# EQEP_0 register map
Vendor: Texas Instruments
Peripheral module from a debugger description file (folder 66AK2G0x_66AK2G1x).
Registers are 16-bit, read-write, reset 0x0 unless marked. A register's access mark holds for its fields unless they carry their own. Offsets are as the file gives them; lines under a group give offsets from that group; [hi:lo] are bit positions; {n}, {i} and the like mark numbered series; 'fields as' and 'values as' point back to an identical list; <NAME> marks a mode.

## EQEP_0
0x00 EQEP_QPOSCNT 32-bit
  [31:0] QPOSCNT — This 32 bit position counter register counts up/down on every eQEP pulse based on direction input. This counter acts as a position integrator whose count value is proportional to position from a give reference point.
0x04 EQEP_QPOSINIT 32-bit
  [31:0] QPOSINIT — This register contains the position value that is used to initialize the position counter based on external strobe or index event. The position counter can be initialized through software.
0x08 EQEP_QPOSMAX 32-bit
  [31:0] QPOSMAX — This register contains the maximum position counter value.
0x0C EQEP_QPOSCMP 32-bit
  [31:0] QPOSCMP — The position-compare value in this register is compared with the position counter (
0x10 EQEP_QPOSILAT 32-bit ro
  [31:0] QPOSILAT — The position-counter value is latched into this register on an index event as defined by the
0x14 EQEP_QPOSSLAT 32-bit ro
  [31:0] QPOSSLAT — The position-counter value is latched into this register on strobe event as defined by the
0x18 EQEP_QPOSLAT 32-bit ro
  [31:0] QPOSLAT — The position-counter value is latched into this register on unit time out event.
0x1C EQEP_QUTMR 32-bit
  [31:0] QUTMR — This register acts as time base for unit time event generation. When this timer value matches with unit time period value, unit time event is generated.
0x20 EQEP_QUPRD 32-bit
  [31:0] QUPRD — This register contains the period count for unit timer to generate periodic unit time events to latch the eQEP position information at periodic interval and optionally to generate interrupt.
0x24 EQEP_QWDTMR
  [15:0] QWDTMR — This register acts as time base for watch dog to detect motor stalls. When this timer value matches with watch dog period value, watch dog timeout interrupt is generated. This register is reset upon edge transition in quadrature-clock indicating the motion.
0x26 EQEP_QWDPRD
  [15:0] QWDPRD — This register contains the time-out count for the eQEP peripheral watch dog timer. When the watchdog timer value matches the watchdog period value, a watchdog timeout interrupt is generated.
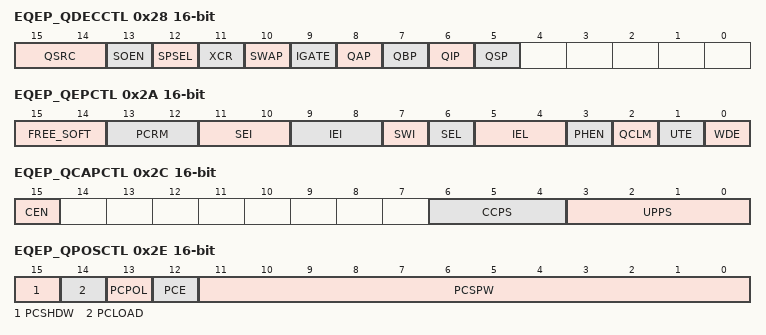
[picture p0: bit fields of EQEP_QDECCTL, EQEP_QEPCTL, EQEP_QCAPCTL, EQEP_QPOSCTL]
0x28 EQEP_QDECCTL access per field
  [15:14] QSRC rw — Position-counter source selection. 0h = Quadrature count mode (QCLK = iCLK, QDIR = iDIR) 1h = Direction-count mode (QCLK = xCLK, QDIR = xDIR) 2h = UP count mode for frequency measurement (QCLK = xCLK, QDIR = 1) 3h = DOWN count mode for frequency measurement (QCLK = xCLK, QDIR = 0)
  [13] SOEN rw — Sync output-enable 0h = Disable position-compare sync output 1h = Enable position-compare sync output
  [12] SPSEL rw — Sync output pin selection 0h = Index pin is used for sync output 1h = Strobe pin is used for sync output
  [11] XCR rw — External clock rate 0h = 2x resolution: Count the rising/falling edge 1h = 1x resolution: Count the rising edge only
  [10] SWAP rw — Swap quadrature clock inputs. This swaps the input to the quadrature decoder, reversing the counting direction. 0h = Quadrature-clock inputs are not swapped 1h = Quadrature-clock inputs are swapped
  [9] IGATE rw — Index pulse gating option 0h = Disable gating of Index pulse 1h = Gate the index pin with strobe
  [8] QAP rw — QEPA input polarity 0h = No effect 1h = Negates QEPA input
  [7] QBP rw — QEPB input polarity 0h = No effect 1h = Negates QEPB input
  [6] QIP rw — QEPI input polarity 0h = No effect 1h = Negates QEPI input
  [5] QSP rw — QEPS input polarity 0h = No effect 1h = Negates QEPS input
0x2A EQEP_QEPCTL
  [15:14] FREE_SOFT — Emulation Control Bits. In the values 0 through 3 listed below, x is different for the four following behaviors. EQEP_QPOSCNT behavior, x refers to the Position counter. QWDTMR behavior, x refers to the Watchdog counter. QUTMR behavior, x refers to the Unit timer. QCTMR behavior, x refers to the Capture timer. 0h = x stops immediately. For QPOSCNT behavior, the stop is on emulation suspend. 1h = x continues to count until the rollover. 2h = x is unaffected by emulation suspend. 3h = x is unaffected by emulation suspend.
  [13:12] PCRM — Position counter reset mode 0h = Position counter reset on an index event 1h = Position counter reset on the maximum position 2h = Position counter reset on the first index event 3h = Position counter reset on a unit time event
  [11:10] SEI — Strobe event initialization of position counter 0h = Does nothing (action disabled) 1h = Does nothing (action disabled) 2h = Initializes the position counter on rising edge of the QEPS signal 3h = Clockwise Direction: Initializes the position counter on the rising edge of QEPS strobe. Counter Clockwise Direction: Initializes the position counter on the falling edge of QEPS strobe
  [9:8] IEI — Index event initialization of position counter 0h = Do nothing (action disabled) 1h = Do nothing (action disabled) 2h = Initializes the position counter on the rising edge of the QEPI signal (QPOSCNT = QPOSINIT) 3h = Initializes the position counter on the falling edge of QEPI signal (QPOSCNT = QPOSINIT)
  [7] SWI — Software initialization of position counter 0h = Do nothing (action disabled) 1h = Initialize position counter, this bit is cleared automatically
  [6] SEL — Strobe event latch of position counter 0h = The position counter is latched on the rising edge of QEPS strobe (QPOSSLAT = POSCCNT). Latching on the falling edge can be done by inverting the strobe input using the QSP bit in the EQEP_QDECCTL register. 1h = Clockwise Direction: Position counter is latched on rising edge of QEPS strobe. Counter Clockwise Direction: Position counter is latched on falling edge of QEPS strobe.
  [5:4] IEL — Index event latch of position counter (software index marker) 0h = Reserved 1h = Latches position counter on rising edge of the index signal 2h = Latches position counter on falling edge of the index signal 3h = Software index marker. Latches the position counter and quadrature direction flag on index event marker. The position counter is latched to theEQEP_QPOSILAT register and the direction flag is latched in the EQEP_QEPSTS[QDLF] bit. This mode is useful for software index marking.
  [3] PHEN — Quadrature position counter enable/software reset 0h = Reset the eQEP peripheral internal operating flags/read-only registers. Control/configuration registers are not disturbed by a software reset. 1h = eQEP position counter is enabled
  [2] QCLM — eQEP capture latch mode 0h = Latch on position counter read by CPU. Capture timer and capture period values are latched into EQEP_QCTMRLAT and EQEP_QCPRDLAT registers when CPU reads the EQEP_QPOSCNT register. 1h = Latch on unit time out. Position counter, capture timer and capture period values are latched intoEQEP_QPOSLAT, EQEP_QCTMRLAT and EQEP_QCPRDLAT registers on unit time out.
  [1] UTE — eQEP unit timer enable 0h = Disable eQEP unit timer 1h = Enable unit timer
  [0] WDE — eQEP watchdog enable 0h = Disable the eQEP watchdog timer 1h = Enable the eQEP watchdog timer
0x2C EQEP_QCAPCTL access per field
  [15] CEN rw — Enable eQEP capture 0h = eQEP capture unit is disabled 1h = eQEP capture unit is enabled
  [6:4] CCPS rw — eQEP capture timer clock prescaler 0h = CAPCLK = SYSCLKOUT/1 1h = CAPCLK = SYSCLKOUT/2 2h = CAPCLK = SYSCLKOUT/4 3h = CAPCLK = SYSCLKOUT/8 4h = CAPCLK = SYSCLKOUT/16 5h = CAPCLK = SYSCLKOUT/32 6h = CAPCLK = SYSCLKOUT/64 7h = CAPCLK = SYSCLKOUT/128
  [3:0] UPPS rw — Unit position event prescaler 0h = UPEVNT = QCLK/1 1h = UPEVNT = QCLK/2 2h = UPEVNT = QCLK/4 3h = UPEVNT = QCLK/8 4h = UPEVNT = QCLK/16 5h = UPEVNT = QCLK/32 6h = UPEVNT = QCLK/64 7h = UPEVNT = QCLK/128 8h = UPEVNT = QCLK/256 9h = UPEVNT = QCLK/512 Ah = UPEVNT = QCLK/1024 Bh = UPEVNT = QCLK/2048 Ch = Reserved Dh = Reserved Eh = Reserved Fh = Reserved
0x2E EQEP_QPOSCTL
  [15] PCSHDW — Position-compare shadow enable 0h = Shadow disabled, load Immediate 1h = Shadow enabled
  [14] PCLOAD — Position-compare shadow load mode 0h = Load on QPOSCNT = 0 1h = Load when QPOSCNT = QPOSCMP
  [13] PCPOL — Polarity of sync output 0h = Active HIGH pulse output 1h = Active LOW pulse output
  [12] PCE — Position-compare enable/disable 0h = Disable position compare unit 1h = Enable position compare unit
  [11:0] PCSPW — Select-position-compare sync output pulse width ... 0h = 1 × 4 × SYSCLKOUT cycles 1h = 2 × 4 × SYSCLKOUT cycles 2h = 3 × 4 × SYSCLKOUT cycles to 4096 × 4 × SYSCLKOUT cycles FFFh = 3 × 4 × SYSCLKOUT cycles to 4096 × 4 × SYSCLKOUT cycles
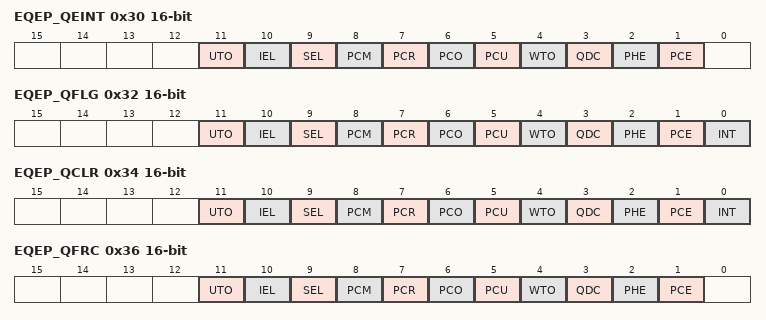
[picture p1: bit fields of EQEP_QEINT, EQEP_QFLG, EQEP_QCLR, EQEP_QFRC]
0x30 EQEP_QEINT access per field
  [11] UTO rw — Unit time out interrupt enable 0h = Interrupt is disabled 1h = Interrupt is enabled
  [10] IEL rw — Index event latch interrupt enable 0h = Interrupt is disabled 1h = Interrupt is enabled
  [9] SEL rw — Strobe event latch interrupt enable 0h = Interrupt is disabled 1h = Interrupt is enabled
  [8] PCM rw — Position-compare match interrupt enable 0h = Interrupt is disabled 1h = Interrupt is enabled
  [7] PCR rw — Position-compare ready interrupt enable 0h = Interrupt is disabled 1h = Interrupt is enabled
  [6] PCO rw — Position counter overflow interrupt enable 0h = Interrupt is disabled 1h = Interrupt is enabled
  [5] PCU rw — Position counter underflow interrupt enable 0h = Interrupt is disabled 1h = Interrupt is enabled
  [4] WTO rw — Watchdog time out interrupt enable 0h = Interrupt is disabled 1h = Interrupt is enabled
  [3] QDC rw — Quadrature direction change interrupt enable 0h = Interrupt is disabled 1h = Interrupt is enabled
  [2] PHE rw — Quadrature phase error interrupt enable 0h = Interrupt is disabled 1h = Interrupt is enabled
  [1] PCE rw — Position counter error interrupt enable 0h = Interrupt is disabled 1h = Interrupt is enabled
0x32 EQEP_QFLG ro
  [11] UTO — Unit time out interrupt flag 0h = No interrupt generated 1h = Set by eQEP unit timer period match
  [10] IEL — Index event latch interrupt flag 0h = No interrupt generated 1h = This bit is set after latching the QPOSCNT to QPOSILAT
  [9] SEL — Strobe event latch interrupt flag 0h = No interrupt generated 1h = This bit is set after latching the QPOSCNT toEQEP_QPOSSLAT
  [8] PCM — eQEP compare match event interrupt flag 0h = No interrupt generated 1h = This bit is set on position-compare match
  [7] PCR — Position-compare ready interrupt flag 0h = No interrupt generated 1h = This bit is set after transferring the shadow register value to the active position compare register.
  [6] PCO — Position counter overflow interrupt flag 0h = No interrupt generated 1h = This bit is set on position counter overflow.
  [5] PCU — Position counter underflow interrupt flag 0h = No interrupt generated 1h = This bit is set on position counter underflow.
  [4] WTO — Watchdog timeout interrupt flag 0h = No interrupt generated 1h = Set by watch dog timeout
  [3] QDC — Quadrature direction change interrupt flag 0h = No interrupt generated 1h = This bit is set during change of direction
  [2] PHE — Quadrature phase error interrupt flag 0h = No interrupt generated 1h = Set on simultaneous transition of QEPA and QEPB
  [1] PCE — Position counter error interrupt flag 0h = No interrupt generated 1h = Position counter error
  [0] INT — Global interrupt status flag 0h = No interrupt generated 1h = Interrupt was generated
0x34 EQEP_QCLR access per field
  [11] UTO rw — Clear unit time out interrupt flag 0h = No effect 1h = Clears the interrupt flag
  [10] IEL rw — Clear index event latch interrupt flag 0h = No effect 1h = Clears the interrupt flag
  [9] SEL rw — Clear strobe event latch interrupt flag 0h = No effect 1h = Clears the interrupt flag
  [8] PCM rw — Clear eQEP compare match event interrupt flag 0h = No effect 1h = Clears the interrupt flag
  [7] PCR rw — Clear position-compare ready interrupt flag 0h = No effect 1h = Clears the interrupt flag
  [6] PCO rw — Clear position counter overflow interrupt flag 0h = No effect 1h = Clears the interrupt flag
  [5] PCU rw — Clear position counter underflow interrupt flag 0h = No effect 1h = Clears the interrupt flag
  [4] WTO rw — Clear watchdog timeout interrupt flag 0h = No effect 1h = Clears the interrupt flag
  [3] QDC rw — Clear quadrature direction change interrupt flag 0h = No effect 1h = Clears the interrupt flag
  [2] PHE rw — Clear quadrature phase error interrupt flag 0h = No effect 1h = Clears the interrupt flag
  [1] PCE rw — Clear position counter error interrupt flag 0h = No effect 1h = Clears the interrupt flag
  [0] INT rw — Global interrupt clear flag 0h = No effect 1h = Clears the interrupt flag and enables further interrupts to be generated if an event flags is set to 1.
0x36 EQEP_QFRC access per field
  [11] UTO rw — Force unit time out interrupt 0h = No effect 1h = Force the interrupt
  [10] IEL rw — Force index event latch interrupt 0h = No effect 1h = Force the interrupt
  [9] SEL rw — Force strobe event latch interrupt 0h = No effect 1h = Force the interrupt
  [8] PCM rw — Force position-compare match interrupt 0h = No effect 1h = Force the interrupt
  [7] PCR rw — Force position-compare ready interrupt 0h = No effect 1h = Force the interrupt
  [6] PCO rw — Force position counter overflow interrupt 0h = No effect 1h = Force the interrupt
  [5] PCU rw — Force position counter underflow interrupt 0h = No effect 1h = Force the interrupt
  [4] WTO rw — Force watchdog time out interrupt 0h = No effect 1h = Force the interrupt
  [3] QDC rw — Force quadrature direction change interrupt 0h = No effect 1h = Force the interrupt
  [2] PHE rw — Force quadrature phase error interrupt 0h = No effect 1h = Force the interrupt
  [1] PCE rw — Force position counter error interrupt 0h = No effect 1h = Force the interrupt
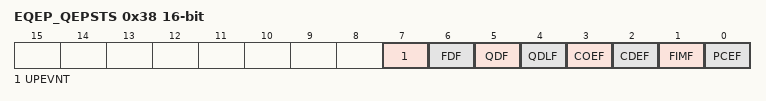
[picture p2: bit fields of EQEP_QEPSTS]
0x38 EQEP_QEPSTS access per field
  [7] UPEVNT ro — Unit position event flag 0h = No unit position event detected 1h = Unit position event detected. Write 1 to clear.
  [6] FDF ro — Direction on the first index marker. Status of the direction is latched on the first index event marker. 0h = Counter-clockwise rotation (or reverse movement) on the first index event 1h = Clockwise rotation (or forward movement) on the first index event
  [5] QDF ro — Quadrature direction flag 0h = Counter-clockwise rotation (or reverse movement) 1h = Clockwise rotation (or forward movement)
  [4] QDLF ro — eQEP direction latch flag. Status of direction is latched on every index event marker. 0h = Counter-clockwise rotation (or reverse movement) on index event marker 1h = Clockwise rotation (or forward movement) on index event marker
  [3] COEF rw — Capture overflow error flag 0h = Sticky bit, cleared by writing 1 1h = Overflow occurred in eQEP Capture timer (QEPCTMR)
  [2] CDEF rw — Capture direction error flag 0h = Sticky bit, cleared by writing 1 1h = Direction change occurred between the capture position event.
  [1] FIMF rw — First index marker flag 0h = Sticky bit, cleared by writing 1 1h = Set by first occurrence of index pulse
  [0] PCEF ro — Position counter error flag. This bit is not sticky and it is updated for every index event. 0h = No error occurred during the last index transition. 1h = Position counter error
0x3A EQEP_QCTMR
  [15:0] QCTMR — This register provides time base for edge capture unit.
0x3C EQEP_QCPRD
  [15:0] QCPRD — This register holds the period count value between the last successive eQEP position events.
0x3E EQEP_QCTMRLAT ro
  [15:0] QCTMRLAT — The eQEP capture timer value can be latched into this register on two events, that is, unit timeout event, reading the eQEP position counter.
0x40 EQEP_QCPRDLAT
  [15:0] QCPRDLAT — eQEP capture period value can be latched into this register on two events, that is, unit timeout event, reading the eQEP position counter.
0x5C EQEP_REVID 32-bit ro reset not defined
  [31:0] REVISION — IP Revision
